# GD32E51x_CL register map
File version: 1.0
CPU: CM33 r0p4, little endian, MPU, FPU, 4 interrupt priority bits
Registers are 32-bit, read-write, reset 0x0 unless marked. A register's access mark holds for its fields unless they carry their own. Offsets are from the block's base; [hi:lo] are bit positions; {n}, {i} and the like mark numbered series.

## MASTER_TIMER — SHRTIMER Master TIMER
Base 0x40017400
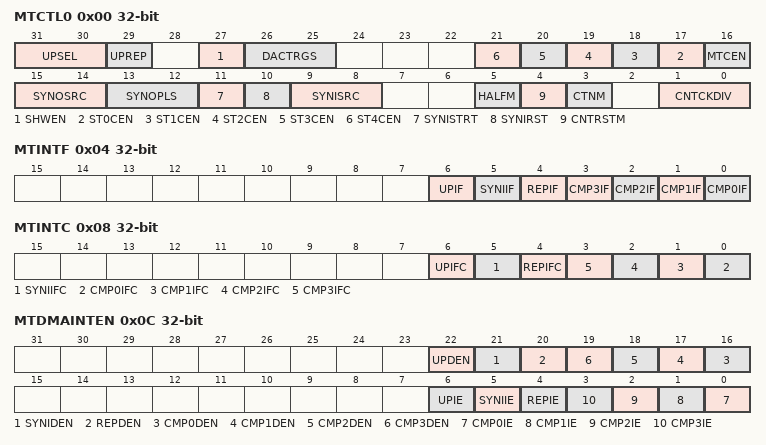
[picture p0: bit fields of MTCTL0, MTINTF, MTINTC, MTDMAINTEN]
0x00 MTCTL0 — SHRTIMER Master_TIMER control register 0
  [31:30] UPSEL — Update event selection
  [29] UPREP — Update event generated by repetition event
  [27] SHWEN — Shadow registers enable
  [26:25] DACTRGS — Trigger source to DAC
  [n+17] ST{n}CEN (n=0..4) — The counter of Slave_TIMER{n} enable
  [16] MTCEN — The counter of Master_TIMER enable
  [15:14] SYNOSRC — Synchronization output source
  [13:12] SYNOPLS — Synchronization output pulse
  [11] SYNISTRT — Synchronization input start counter
  [10] SYNIRST — Synchronization input reset counter
  [9:8] SYNISRC — Synchronization input source
  [5] HALFM — Half mode
  [4] CNTRSTM — Counter reset mode
  [3] CTNM — Continuous mode
  [1:0] CNTCKDIV — Counter clock division
0x04 MTINTF ro — SHRTIMER Master_TIMER interrupt flag register
  [6] UPIF — Update interrupt flag
  [5] SYNIIF — Synchronization input interrupt flag
  [4] REPIF — Repetition interrupt flag
  [n] CMP{n}IF (n=0..3) — Compare {n} interrupt flag
0x08 MTINTC wo — SHRTIMER Master_TIMER interrupt flag clear register
  [6] UPIFC — Clear update interrupt flag
  [5] SYNIIFC — Clear synchronization input interrupt flag
  [4] REPIFC — Clear repetition interrupt flag
  [n] CMP{n}IFC (n=0..3) — Clear compare {n} interrupt flag
0x0C MTDMAINTEN — SHRTIMER Master_TIMER DMA and interrupt enable register
  [22] UPDEN — Update DMA request enable
  [21] SYNIDEN — Synchronization input DMA request enable
  [20] REPDEN — Repetition DMA request enable
  [n+16] CMP{n}DEN (n=0..3) — Compare {n} DMA request enable
  [6] UPIE — Update interrupt enable
  [5] SYNIIE — Synchronization input interrupt enable
  [4] REPIE — Repetition interrupt enable
  [n] CMP{n}IE (n=0..3) — Compare {n} interrupt enable
0x10 MTCNT — SHRTIMER Master_TIMER counter register
  [15:0] CNT — The current counter value
0x14 MTCAR — SHRTIMER Master_TIMER counter auto reload register
  [15:0] CARL — Counter auto reload value
0x18 MTCREP — SHRTIMER Master_TIMER counter repetition register
  [7:0] CREP — Counter repetition value
0x1C MTCMP0V — SHRTIMER Master_TIMER compare 0 value register
  [15:0] CMP0VAL — Compare 0 value
{0x20+4i} MTCMP{i}V (i=1..3) — SHRTIMER Master_TIMER compare {i} value register
  [15:0] CMP{i}VAL — Compare {i} value
0x7C MTACTL — SHRTIMER Master_TIMER additional control register
  [3] CNTCKDIV_3 — Counter clock division

## NVIC — Nested Vectored Interrupt Controller
Base 0xE000E100
0x00 ISER — Interrupt Set Enable Register
  [31:0] SETENA
0x80 ICER — Interrupt Clear Enable Register
  [31:0] CLRENA
0x100 ISPR — Interrupt Set-Pending Register
  [31:0] SETPEND
0x180 ICPR — Interrupt Clear-Pending Register
  [31:0] CLRPEND
0x200 IABR — Interrupt Active bit Register
{0x300+i} IPR{i} 8-bit (i=0..67) — Interrupt Priority Register {i}
  [7:0] PRI_{i:02}
0xE00 STIR wo — Software Trigger Interrupt Register

## PMU — Power management unit
Base 0x40007000
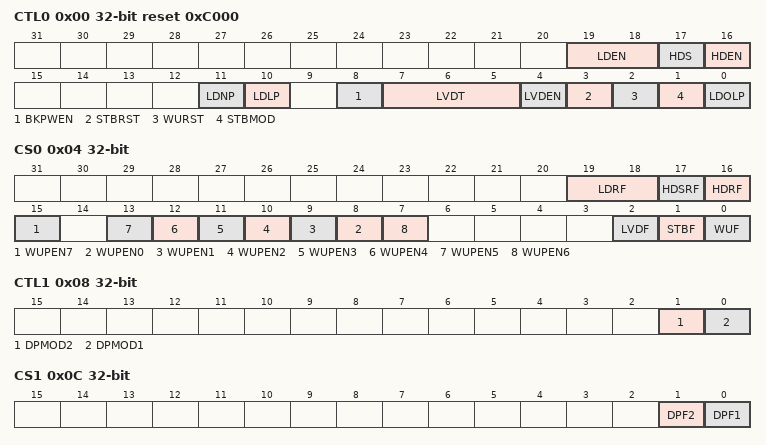
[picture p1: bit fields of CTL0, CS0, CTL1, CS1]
0x00 CTL0 reset 0xC000 — power control register 0
  [19:18] LDEN — Low-driver mode enable in Deep-sleep mode
  [17] HDS — High-driver mode switch
  [16] HDEN — High-driver mode enable
  [11] LDNP — Low-driver mode when use normal power LDO
  [10] LDLP — Low-driver mode when use low power LDO.
  [8] BKPWEN — Backup Domain Write Enable
  [7:5] LVDT — Low Voltage Detector Threshold
  [4] LVDEN — Low Voltage Detector Enable
  [3] STBRST — Standby Flag Reset
  [2] WURST — Wakeup Flag Reset
  [1] STBMOD — Standby Mode
  [0] LDOLP — LDO Low Power Mode
0x04 CS0 access per field — power control/status register 0
  [19:18] LDRF rw — Low-driver mode ready flag
  [17] HDSRF ro — High-driver switch ready flag
  [16] HDRF ro — High-driver ready flag
  [15] WUPEN7 rw — Enable WKUP Pin7(PF8)
  [n+8] WUPEN{n} rw (n=0..5) — Enable WKUP pin{n}
  [7] WUPEN6 rw — Enable WKUP pin6
  [2] LVDF ro — Low Voltage Detector Status Flag
  [1] STBF ro — Standby flag
  [0] WUF ro — Wakeup flag
0x08 CTL1 — power control register 1
  [1] DPMOD2 — Enable deep-sleep 2 mode
  [0] DPMOD1 — Enable deep-sleep 1 mode
0x0C CS1 — power control and status register 1
  [1] DPF2 — Deep-sleep 2 mode status flag
  [0] DPF1 — Deep-sleep1 mode status flag
